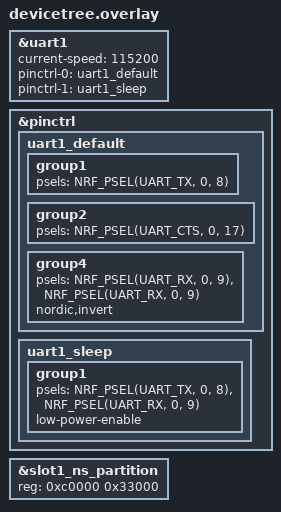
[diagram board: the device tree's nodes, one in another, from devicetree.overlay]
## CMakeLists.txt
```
cmake_minimum_required(VERSION 3.20.0)
find_package(Zephyr REQUIRED HINTS $ENV{ZEPHYR_BASE})

project(testUART)

target_sources(app PRIVATE src/main.c)
```

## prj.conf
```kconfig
CONFIG_SERIAL=y
CONFIG_PINCTRL=y
CONFIG_MAIN_STACK_SIZE=2048
```

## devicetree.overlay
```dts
&uart1 {
    status = "okay";
    current-speed = <115200>;
    pinctrl-0 = <&uart1_default>;
    pinctrl-1 = <&uart1_sleep>;
    pinctrl-names = "default", "sleep";
};

&pinctrl {
    uart1_default: uart1_default {
        group1 {
            psels = <NRF_PSEL(UART_TX, 0, 8)>;
        };

        group2 {
            psels = <NRF_PSEL(UART_CTS, 0, 17)>;
        };

        group4 {
            psels = <NRF_PSEL(UART_RX, 0, 9)>, <NRF_PSEL(UART_RX, 0, 9)>;
            nordic,invert;
        };
    };

    uart1_sleep: uart1_sleep {
        group1 {
            psels = <NRF_PSEL(UART_TX, 0, 8)>,
                    <NRF_PSEL(UART_RX, 0, 9)>;
            low-power-enable;
        };
    };

};


&slot1_ns_partition {
    reg = <0xc0000 0x33000>;
};
```

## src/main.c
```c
#include <zephyr/device.h>
#include <zephyr/devicetree.h>
#include <zephyr/drivers/uart.h>
#include <zephyr/kernel.h>

#define UART_NODE DT_NODELABEL(uart1)


#include <zephyr/kernel.h>
#include <zephyr/device.h>
#include <zephyr/drivers/uart.h>
#include <string.h>

#define MAX_LINE_LEN 128

const struct device *uart_dev;
char rx_buffer[MAX_LINE_LEN];
int rx_index = 0;

void read_uart_line_blocking(struct device *uart_dev) {
    uint8_t ch;
    int ret;

    while (1) {
        ret = uart_poll_in(uart_dev, &ch);
        if (ret == 0) {
            // Eco inmediato del carácter
            uart_poll_out(uart_dev, ch);

            if (ch == '\r' || ch == '\n') {
                // Fin de línea
                rx_buffer[rx_index] = '\0';  // Termina el string
                uart_poll_out(uart_dev, '\n');

                //printk("Línea recibida: %s\n", rx_buffer);

                // Procesar la línea aquí si deseas...

                // Reiniciar para la siguiente línea
                rx_index = 0;
                memset(rx_buffer, 0, sizeof(rx_buffer));
            } else {
                // Agregar carácter al buffer si hay espacio
                if (rx_index < MAX_LINE_LEN - 1) {
                    rx_buffer[rx_index++] = ch;
                }
            }
        } else {
            k_sleep(K_MSEC(1));  // Pequeña pausa si no hay datos
        }
    }
}


void main(void) {
    const struct device *uart_dev = DEVICE_DT_GET(UART_NODE);

    if (!device_is_ready(uart_dev)) {
        return;
    }

    /*uint8_t ch;
    int ret;

    while (1) {
        uart_poll_out(uart_dev, 'H');
        uart_poll_out(uart_dev, 'i');
        uart_poll_out(uart_dev, '\n');

        ret = uart_poll_in(uart_dev, &ch);
        if (ret == 0) {
            uart_poll_out(uart_dev, ch); // Eco simple
            uart_poll_out(uart_dev, '\n');
        }

        k_sleep(K_MSEC(100));
    }*/
    read_uart_line_blocking(uart_dev);
}


/*
#include <zephyr/device.h>
#include <zephyr/devicetree.h>
#include <zephyr/drivers/uart.h>
#include <zephyr/kernel.h>

#define UART_NODE DT_NODELABEL(uart1)

void main(void) {
    const struct device *uart_dev = DEVICE_DT_GET(UART_NODE);

    if (!device_is_ready(uart_dev)) {
        return;
    }

    uint8_t ch;
    int ret;

    while (1) {
        uart_poll_out(uart_dev, 'H');
        uart_poll_out(uart_dev, 'i');
        uart_poll_out(uart_dev, '\n');

        ret = uart_poll_in(uart_dev, &ch);
        if (ret == 0) {
            uart_poll_out(uart_dev, ch); // Eco simple
            uart_poll_out(uart_dev, '\n');
            printk("Received: %c\n", ch);
        }

        k_sleep(K_MSEC(100));
    }
}


*/
```
